# ESP32-S2 register map
Vendor: ESPRESSIF SYSTEMS (SHANGHAI) CO., LTD.; Series: ESP32 S-Series; File version: 20
CPU: Xtensa LX7 r0p0, little endian, no MPU, no FPU, 0 interrupt priority bits
Address unit: 32 bits
Registers are 32-bit, read-write, reset 0x0 unless marked. A register's access mark holds for its fields unless they carry their own. Offsets are from the block's base; [hi:lo] are bit positions; lines under a group give offsets from that group; {n}, {i} and the like mark numbered series; 'fields as' and 'values as' point back to an identical list.

## USB_FS — USB OTG (On-The-Go)
Base 0x60080000
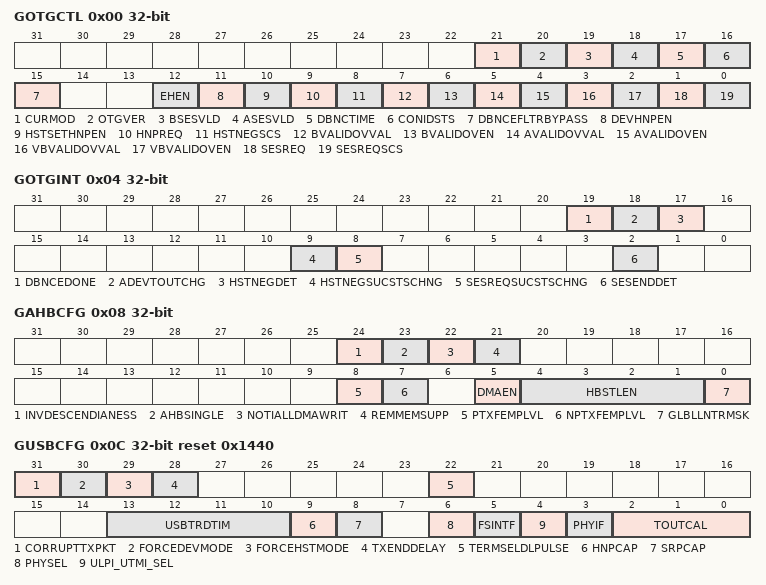
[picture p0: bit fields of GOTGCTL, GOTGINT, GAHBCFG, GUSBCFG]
0x00 GOTGCTL access per field
  [21] CURMOD ro, [20] OTGVER rw, [19] BSESVLD ro, [18] ASESVLD ro, [17] DBNCTIME ro, [16] CONIDSTS ro, [15] DBNCEFLTRBYPASS rw, [12] EHEN rw, [11] DEVHNPEN rw, [10] HSTSETHNPEN rw, [9] HNPREQ rw, [8] HSTNEGSCS ro, [7] BVALIDOVVAL rw, [6] BVALIDOVEN rw, [5] AVALIDOVVAL rw, [4] AVALIDOVEN rw, [3] VBVALIDOVVAL rw, [2] VBVALIDOVEN rw, [1] SESREQ rw, [0] SESREQSCS ro
0x04 GOTGINT
  [19] DBNCEDONE, [18] ADEVTOUTCHG, [17] HSTNEGDET, [9] HSTNEGSUCSTSCHNG, [8] SESREQSUCSTSCHNG, [2] SESENDDET
0x08 GAHBCFG
  [24] INVDESCENDIANESS, [23] AHBSINGLE, [22] NOTIALLDMAWRIT, [21] REMMEMSUPP, [8] PTXFEMPLVL, [7] NPTXFEMPLVL, [5] DMAEN, [4:1] HBSTLEN, [0] GLBLLNTRMSK
0x0C GUSBCFG access per field reset 0x1440
  [31] CORRUPTTXPKT rw, [30] FORCEDEVMODE rw, [29] FORCEHSTMODE rw, [28] TXENDDELAY rw, [22] TERMSELDLPULSE rw, [13:10] USBTRDTIM rw, [9] HNPCAP rw, [8] SRPCAP rw, [6] PHYSEL ro, [5] FSINTF rw, [4] ULPI_UTMI_SEL ro, [3] PHYIF rw, [2:0] TOUTCAL rw
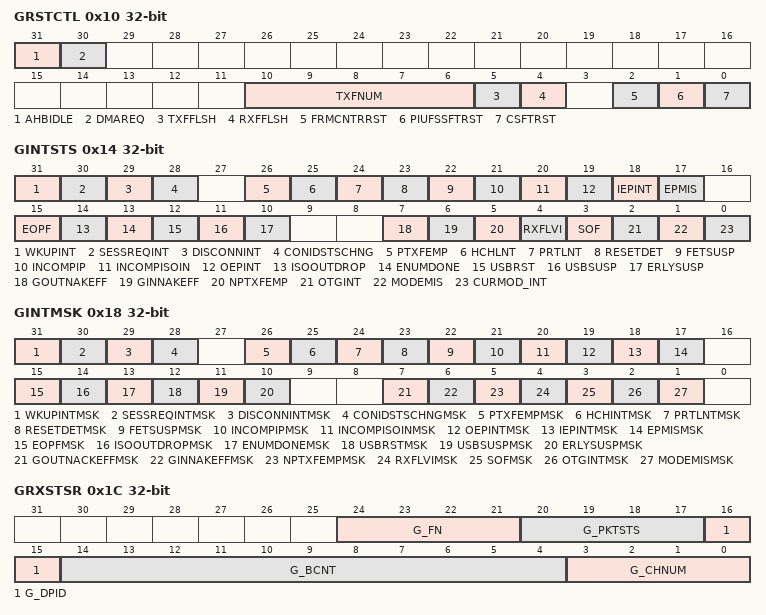
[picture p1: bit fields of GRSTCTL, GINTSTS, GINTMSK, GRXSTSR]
0x10 GRSTCTL access per field
  [31] AHBIDLE ro, [30] DMAREQ ro, [10:6] TXFNUM rw, [5] TXFFLSH rw, [4] RXFFLSH rw, [2] FRMCNTRRST rw, [1] PIUFSSFTRST rw, [0] CSFTRST rw
0x14 GINTSTS access per field
  [31] WKUPINT rw write-1-clears, [30] SESSREQINT rw write-1-clears, [29] DISCONNINT rw write-1-clears, [28] CONIDSTSCHNG rw write-1-clears, [26] PTXFEMP ro write-1-clears, [25] HCHLNT ro write-1-clears, [24] PRTLNT ro write-1-clears, [23] RESETDET rw write-1-clears, [22] FETSUSP rw write-1-clears, [21] INCOMPIP rw write-1-clears, [20] INCOMPISOIN rw write-1-clears, [19] OEPINT ro write-1-clears, [18] IEPINT ro write-1-clears, [17] EPMIS rw write-1-clears, [15] EOPF rw write-1-clears, [14] ISOOUTDROP rw write-1-clears, [13] ENUMDONE rw write-1-clears, [12] USBRST rw write-1-clears, [11] USBSUSP rw write-1-clears, [10] ERLYSUSP rw write-1-clears, [7] GOUTNAKEFF ro write-1-clears, [6] GINNAKEFF ro write-1-clears, [5] NPTXFEMP ro write-1-clears, [4] RXFLVI ro write-1-clears, [3] SOF rw write-1-clears, [2] OTGINT ro write-1-clears, [1] MODEMIS rw write-1-clears, [0] CURMOD_INT ro write-1-clears
0x18 GINTMSK
  [31] WKUPINTMSK, [30] SESSREQINTMSK, [29] DISCONNINTMSK, [28] CONIDSTSCHNGMSK, [26] PTXFEMPMSK, [25] HCHINTMSK, [24] PRTLNTMSK, [23] RESETDETMSK, [22] FETSUSPMSK, [21] INCOMPIPMSK, [20] INCOMPISOINMSK, [19] OEPINTMSK, [18] IEPINTMSK, [17] EPMISMSK, [15] EOPFMSK, [14] ISOOUTDROPMSK, [13] ENUMDONEMSK, [12] USBRSTMSK, [11] USBSUSPMSK, [10] ERLYSUSPMSK, [7] GOUTNACKEFFMSK, [6] GINNAKEFFMSK, [5] NPTXFEMPMSK, [4] RXFLVIMSK, [3] SOFMSK, [2] OTGINTMSK, [1] MODEMISMSK
0x1C GRXSTSR ro
  [24:21] G_FN, [20:17] G_PKTSTS, [16:15] G_DPID, [14:4] G_BCNT, [3:0] G_CHNUM
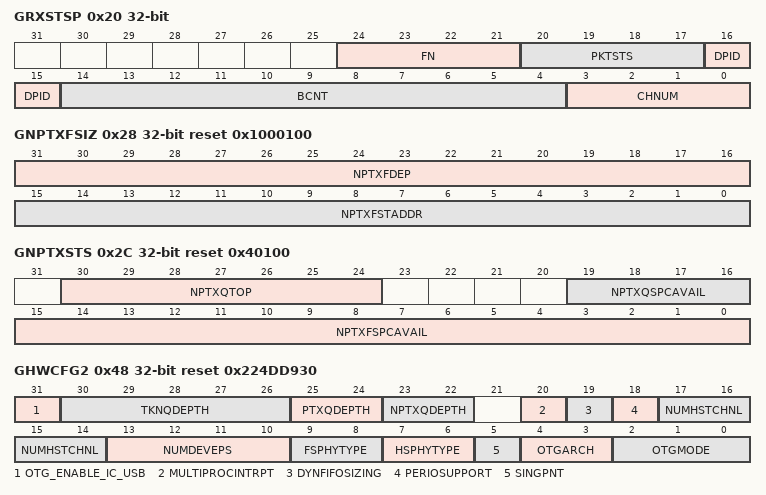
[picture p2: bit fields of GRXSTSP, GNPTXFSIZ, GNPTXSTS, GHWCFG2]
0x20 GRXSTSP ro
  [24:21] FN, [20:17] PKTSTS, [16:15] DPID, [14:4] BCNT, [3:0] CHNUM
0x24 GRXFSIZ reset 0x100
  [15:0] RXFDEP
0x28 GNPTXFSIZ reset 0x1000100
  [31:16] NPTXFDEP, [15:0] NPTXFSTADDR
0x2C GNPTXSTS ro reset 0x40100
  [30:24] NPTXQTOP, [19:16] NPTXQSPCAVAIL, [15:0] NPTXFSPCAVAIL
0x40 GSNPSID ro reset 0x4F54400A
  [31:0] SYNOPSYSID
0x44 GHWCFG1 ro
  [31:0] EPDIR
0x48 GHWCFG2 ro reset 0x224DD930
  [31] OTG_ENABLE_IC_USB, [30:26] TKNQDEPTH, [25:24] PTXQDEPTH, [23:22] NPTXQDEPTH, [20] MULTIPROCINTRPT, [19] DYNFIFOSIZING, [18] PERIOSUPPORT, [17:14] NUMHSTCHNL, [13:10] NUMDEVEPS, [9:8] FSPHYTYPE, [7:6] HSPHYTYPE, [5] SINGPNT, [4:3] OTGARCH, [2:0] OTGMODE
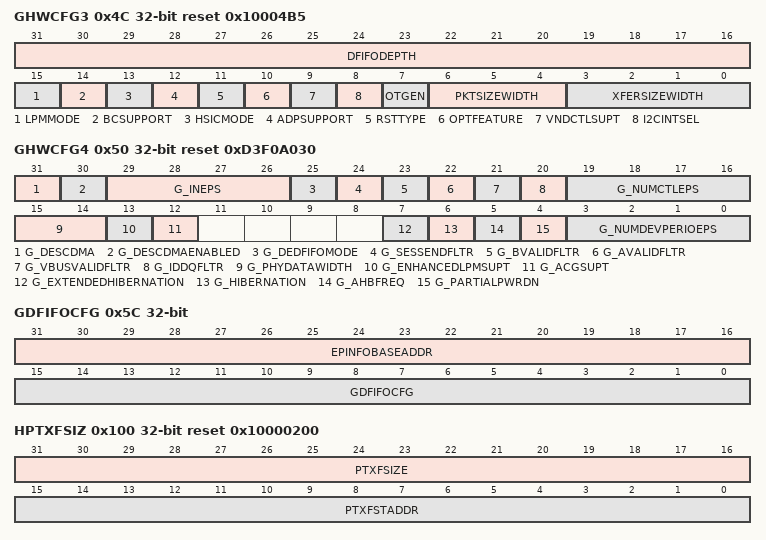
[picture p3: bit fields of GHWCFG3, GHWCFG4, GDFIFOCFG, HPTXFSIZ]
0x4C GHWCFG3 ro reset 0x10004B5
  [31:16] DFIFODEPTH, [15] LPMMODE, [14] BCSUPPORT, [13] HSICMODE, [12] ADPSUPPORT, [11] RSTTYPE, [10] OPTFEATURE, [9] VNDCTLSUPT, [8] I2CINTSEL, [7] OTGEN, [6:4] PKTSIZEWIDTH, [3:0] XFERSIZEWIDTH
0x50 GHWCFG4 ro reset 0xD3F0A030
  [31] G_DESCDMA, [30] G_DESCDMAENABLED, [29:26] G_INEPS, [25] G_DEDFIFOMODE, [24] G_SESSENDFLTR, [23] G_BVALIDFLTR, [22] G_AVALIDFLTR, [21] G_VBUSVALIDFLTR, [20] G_IDDQFLTR, [19:16] G_NUMCTLEPS, [15:14] G_PHYDATAWIDTH, [13] G_ENHANCEDLPMSUPT, [12] G_ACGSUPT, [7] G_EXTENDEDHIBERNATION, [6] G_HIBERNATION, [5] G_AHBFREQ, [4] G_PARTIALPWRDN, [3:0] G_NUMDEVPERIOEPS
0x5C GDFIFOCFG
  [31:16] EPINFOBASEADDR, [15:0] GDFIFOCFG
0x100 HPTXFSIZ reset 0x10000200
  [31:16] PTXFSIZE, [15:0] PTXFSTADDR
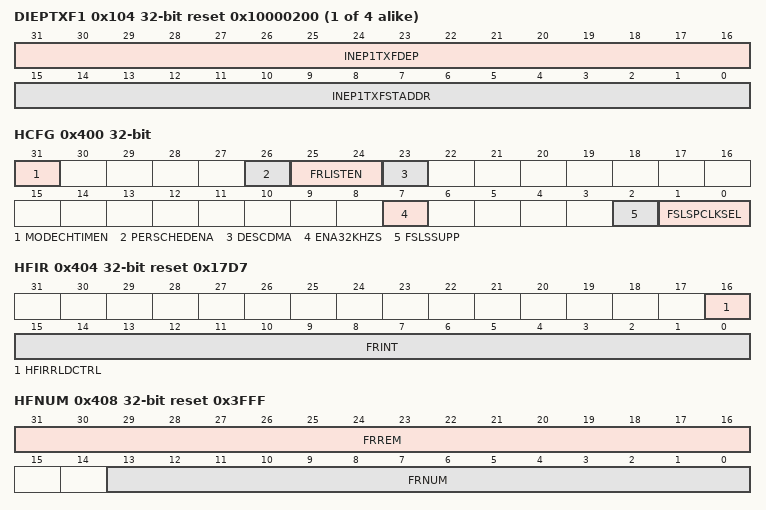
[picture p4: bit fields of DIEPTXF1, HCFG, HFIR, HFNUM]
{0x100+4i} DIEPTXF{i} (i=1..4) reset 0x10000200
  [31:16] INEP1TXFDEP, [15:0] INEP1TXFSTADDR
0x400 HCFG
  [31] MODECHTIMEN, [26] PERSCHEDENA, [25:24] FRLISTEN, [23] DESCDMA, [7] ENA32KHZS, [2] FSLSSUPP, [1:0] FSLSPCLKSEL
0x404 HFIR reset 0x17D7
  [16] HFIRRLDCTRL, [15:0] FRINT
0x408 HFNUM ro reset 0x3FFF
  [31:16] FRREM, [13:0] FRNUM
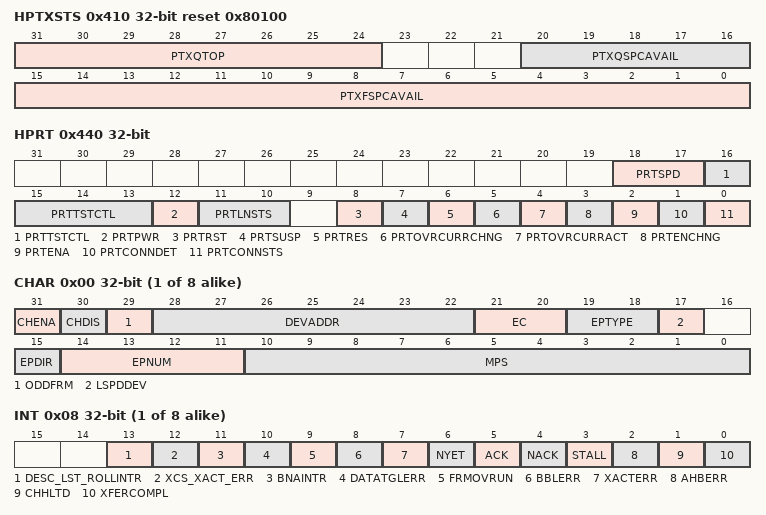
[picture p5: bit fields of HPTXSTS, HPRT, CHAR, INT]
0x410 HPTXSTS ro reset 0x80100
  [31:24] PTXQTOP, [20:16] PTXQSPCAVAIL, [15:0] PTXFSPCAVAIL
0x414 HAINT ro
  [7:0] HAINT
0x418 HAINTMSK
  [7:0] HAINTMSK
0x41C HFLBADDR
0x440 HPRT access per field
  [18:17] PRTSPD ro, [16:13] PRTTSTCTL rw, [12] PRTPWR rw, [11:10] PRTLNSTS ro, [8] PRTRST rw, [7] PRTSUSP rw, [6] PRTRES rw, [5] PRTOVRCURRCHNG rw write-1-clears, [4] PRTOVRCURRACT ro, [3] PRTENCHNG rw write-1-clears, [2] PRTENA rw write-1-clears, [1] PRTCONNDET rw write-1-clears, [0] PRTCONNSTS ro
{0x500+0x20*i} HC{i} (i=0..7) group — Cluster HC{i}, containing HCCHAR?, HCINT?, HCINTMSK?, HCTSIZ?, HCDMA?, HCDMAB?
  0x00 CHAR
    [31] CHENA, [30] CHDIS, [29] ODDFRM, [28:22] DEVADDR, [21:20] EC, [19:18] EPTYPE, [17] LSPDDEV, [15] EPDIR, [14:11] EPNUM, [10:0] MPS
  0x08 INT
    [13] DESC_LST_ROLLINTR write-1-clears, [12] XCS_XACT_ERR write-1-clears, [11] BNAINTR write-1-clears, [10] DATATGLERR write-1-clears, [9] FRMOVRUN write-1-clears, [8] BBLERR write-1-clears, [7] XACTERR write-1-clears, [6] NYET write-1-clears, [5] ACK write-1-clears, [4] NACK write-1-clears, [3] STALL write-1-clears, [2] AHBERR write-1-clears, [1] CHHLTD write-1-clears, [0] XFERCOMPL write-1-clears
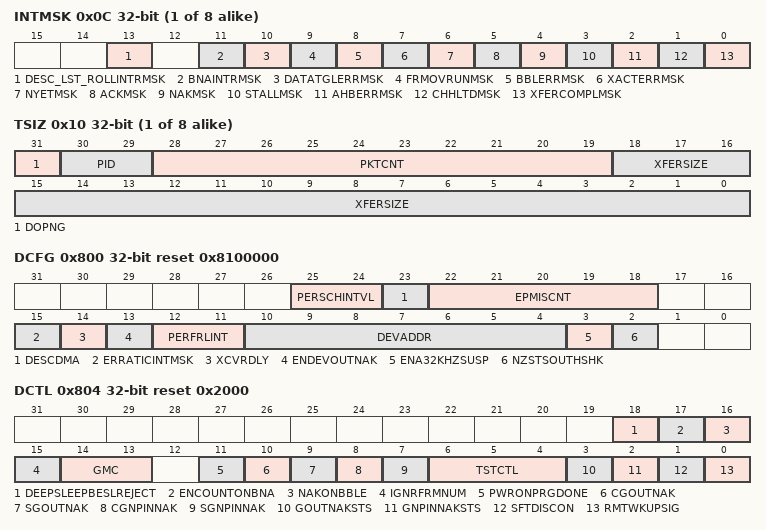
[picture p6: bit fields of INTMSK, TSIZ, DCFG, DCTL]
  0x0C INTMSK
    [13] DESC_LST_ROLLINTRMSK, [11] BNAINTRMSK, [10] DATATGLERRMSK, [9] FRMOVRUNMSK, [8] BBLERRMSK, [7] XACTERRMSK, [6] NYETMSK, [5] ACKMSK, [4] NAKMSK, [3] STALLMSK, [2] AHBERRMSK, [1] CHHLTDMSK, [0] XFERCOMPLMSK
  0x10 TSIZ
    [31] DOPNG, [30:29] PID, [28:19] PKTCNT, [18:0] XFERSIZE
  0x14 DMA
    [31:0] DMAADDR
  0x1C DMAB ro
    [31:0] HCDMAB
0x800 DCFG reset 0x8100000
  [25:24] PERSCHINTVL, [23] DESCDMA, [22:18] EPMISCNT, [15] ERRATICINTMSK, [14] XCVRDLY, [13] ENDEVOUTNAK, [12:11] PERFRLINT, [10:4] DEVADDR, [3] ENA32KHZSUSP, [2] NZSTSOUTHSHK
0x804 DCTL access per field reset 0x2000
  [18] DEEPSLEEPBESLREJECT rw, [17] ENCOUNTONBNA rw, [16] NAKONBBLE rw, [15] IGNRFRMNUM rw, [14:13] GMC rw, [11] PWRONPRGDONE rw, [10] CGOUTNAK wo, [9] SGOUTNAK wo, [8] CGNPINNAK wo, [7] SGNPINNAK wo, [6:4] TSTCTL rw, [3] GOUTNAKSTS ro, [2] GNPINNAKSTS ro, [1] SFTDISCON rw, [0] RMTWKUPSIG rw
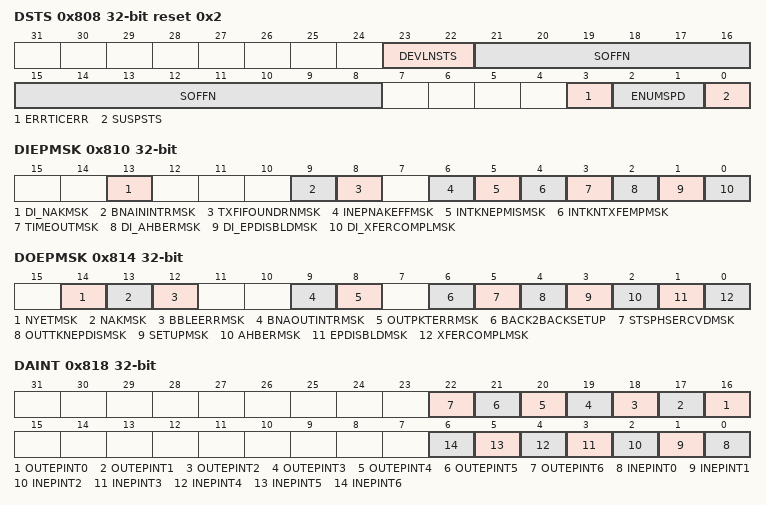
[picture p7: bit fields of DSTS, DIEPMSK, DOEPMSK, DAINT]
0x808 DSTS ro reset 0x2
  [23:22] DEVLNSTS, [21:8] SOFFN, [3] ERRTICERR, [2:1] ENUMSPD, [0] SUSPSTS
0x810 DIEPMSK
  [13] DI_NAKMSK, [9] BNAININTRMSK, [8] TXFIFOUNDRNMSK, [6] INEPNAKEFFMSK, [5] INTKNEPMISMSK, [4] INTKNTXFEMPMSK, [3] TIMEOUTMSK, [2] DI_AHBERMSK, [1] DI_EPDISBLDMSK, [0] DI_XFERCOMPLMSK
0x814 DOEPMSK
  [14] NYETMSK, [13] NAKMSK, [12] BBLEERRMSK, [9] BNAOUTINTRMSK, [8] OUTPKTERRMSK, [6] BACK2BACKSETUP, [5] STSPHSERCVDMSK, [4] OUTTKNEPDISMSK, [3] SETUPMSK, [2] AHBERMSK, [1] EPDISBLDMSK, [0] XFERCOMPLMSK
0x818 DAINT ro
  [n+16] OUTEPINT{n} (n=0..6), [n] INEPINT{n} (n=0..6)
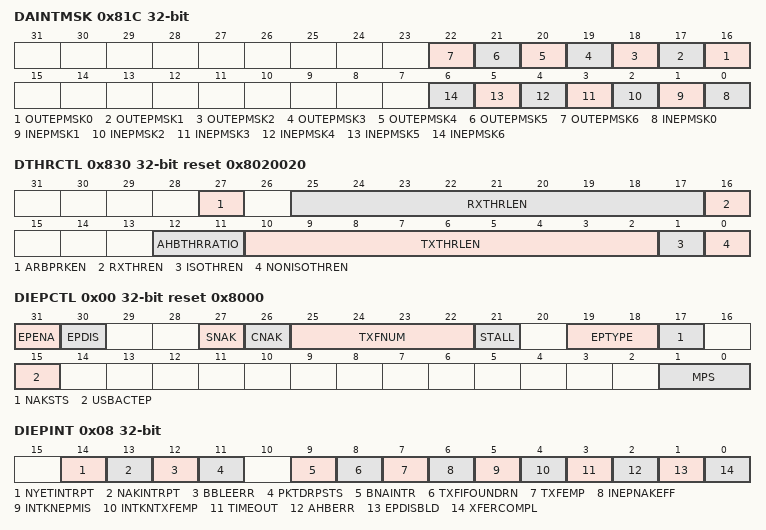
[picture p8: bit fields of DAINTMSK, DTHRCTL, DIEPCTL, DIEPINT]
0x81C DAINTMSK
  [n+16] OUTEPMSK{n} (n=0..6), [n] INEPMSK{n} (n=0..6)
0x828 DVBUSDIS reset 0x17D7
  [15:0] DVBUSDIS
0x82C DVBUSPULSE reset 0x5B8
  [11:0] DVBUSPULSE
0x830 DTHRCTL reset 0x8020020
  [27] ARBPRKEN, [25:17] RXTHRLEN, [16] RXTHREN, [12:11] AHBTHRRATIO, [10:2] TXTHRLEN, [1] ISOTHREN, [0] NONISOTHREN
0x834 DIEPEMPMSK
  [15:0] D_INEPTXFEMPMSK
0x900 IN_EP0 group — Device IN endpoint 0
  0x00 DIEPCTL access per field reset 0x8000
    [31] EPENA rw, [30] EPDIS rw, [27] SNAK wo, [26] CNAK wo, [25:22] TXFNUM rw, [21] STALL rw, [19:18] EPTYPE ro, [17] NAKSTS ro, [15] USBACTEP ro, [1:0] MPS rw
  0x08 DIEPINT access per field
    [14] NYETINTRPT rw, [13] NAKINTRPT rw, [12] BBLEERR rw, [11] PKTDRPSTS rw, [9] BNAINTR rw, [8] TXFIFOUNDRN rw, [7] TXFEMP ro, [6] INEPNAKEFF rw, [5] INTKNEPMIS rw, [4] INTKNTXFEMP rw, [3] TIMEOUT rw, [2] AHBERR rw, [1] EPDISBLD rw, [0] XFERCOMPL rw
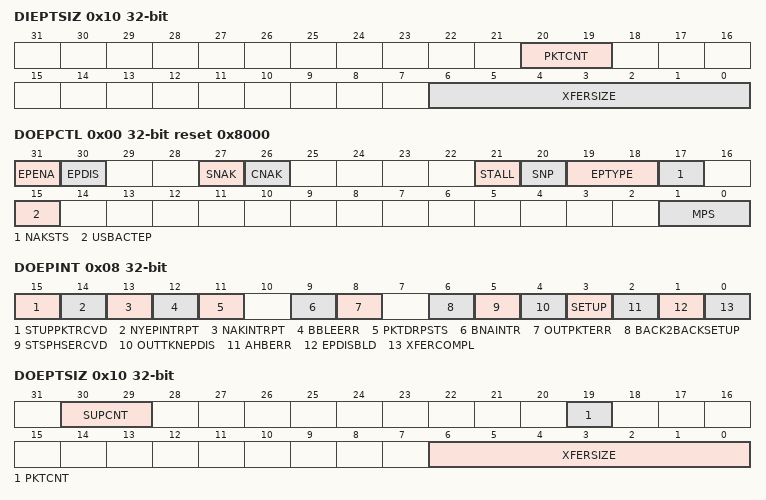
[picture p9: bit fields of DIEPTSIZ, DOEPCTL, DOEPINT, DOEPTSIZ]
  0x10 DIEPTSIZ
    [20:19] PKTCNT, [6:0] XFERSIZE
  0x14 DIEPDMA
    [31:0] DMAADDR
  0x18 DTXFSTS ro
    [15:0] INEPTXFSPCAVAIL
  0x1C DIEPDMAB ro
    [31:0] DMABUFFERADDR
{0x900+0x20*i} IN_EP{i} (i=1..6) group — Device IN endpoints 1-6
  0x00 DIEPCTL access per field reset 0x8000
    [31] EPENA rw, [30] EPDIS rw, [29] SETD1PID wo, [28] SETD0PID wo, [27] SNAK wo, [26] CNAK wo, [25:22] TXFNUM rw, [21] STALL rw, [19:18] EPTYPE rw, [17] NAKSTS ro, [15] USBACTEP rw, [10:0] MPS rw
  0x08 DIEPINT access per field
    fields as IN_EP0.DIEPINT
  0x10 DIEPTSIZ
    [28:19] PKTCNT, [18:0] XFERSIZE
  0x14 DIEPDMA
    [31:0] DMAADDR
  0x18 DTXFSTS ro
    [15:0] INEPTXFSPCAVAIL
  0x1C DIEPDMAB ro
    [31:0] DMABUFFERADDR
0xB00 OUT_EP0 group — Device OUT endpoint 0
  0x00 DOEPCTL access per field reset 0x8000
    [31] EPENA rw, [30] EPDIS ro, [27] SNAK wo, [26] CNAK wo, [21] STALL rw, [20] SNP rw, [19:18] EPTYPE ro, [17] NAKSTS ro, [15] USBACTEP ro, [1:0] MPS ro
  0x08 DOEPINT
    [15] STUPPKTRCVD, [14] NYEPINTRPT, [13] NAKINTRPT, [12] BBLEERR, [11] PKTDRPSTS, [9] BNAINTR, [8] OUTPKTERR, [6] BACK2BACKSETUP, [5] STSPHSERCVD, [4] OUTTKNEPDIS, [3] SETUP, [2] AHBERR, [1] EPDISBLD, [0] XFERCOMPL
  0x10 DOEPTSIZ
    [30:29] SUPCNT, [19] PKTCNT, [6:0] XFERSIZE
  0x14 DOEPDMA
    [31:0] DMAADDR
  0x1C DOEPDMAB
    [31:0] DMABUFFERADDR
{0xB00+0x20*i} OUT_EP{i} (i=1..6) group — Device OUT endpoints 1-6
  0x00 DOEPCTL access per field reset 0x8000
    [31] EPENA rw, [30] EPDIS rw, [29] SETD1PID wo, [28] SETD0PID wo, [27] SNAK wo, [26] CNAK wo, [21] STALL rw, [20] SNP rw, [19:18] EPTYPE rw, [17] NAKSTS ro, [15] USBACTEP rw, [10:0] MPS rw
  0x08 DOEPINT
    fields as OUT_EP0.DOEPINT
  0x10 DOEPTSIZ
    [30:29] SUPCNT, [28:19] PKTCNT, [18:0] XFERSIZE
  0x14 DOEPDMA
    [31:0] DMAADDR
  0x1C DOEPDMAB
    [31:0] DMABUFFERADDR
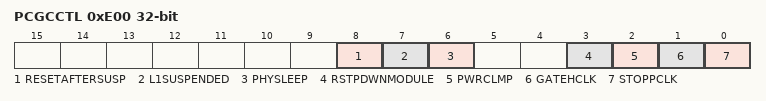
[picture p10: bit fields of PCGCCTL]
0xE00 PCGCCTL access per field
  [8] RESETAFTERSUSP rw, [7] L1SUSPENDED ro, [6] PHYSLEEP ro, [3] RSTPDWNMODULE rw, [2] PWRCLMP rw, [1] GATEHCLK rw, [0] STOPPCLK rw
{0x1000+0x1000*i} FIFO{i} (i=0..15) — Read and write data to the USB FIFOs through this register.
  [31:0] WORD
